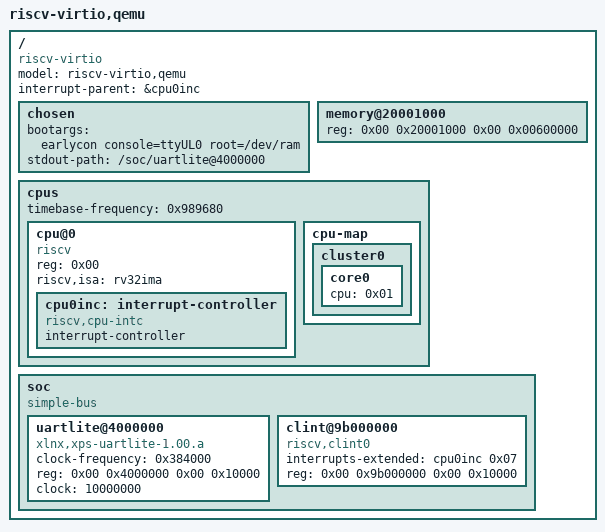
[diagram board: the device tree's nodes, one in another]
/dts-v1/;

/ {
	#address-cells = <0x02>;
	#size-cells = <0x02>;
	compatible = "riscv-virtio";
	model = "riscv-virtio,qemu";
	interrupt-parent = "&cpu0inc";

	chosen {
		bootargs = "earlycon console=ttyUL0 root=/dev/ram";
		stdout-path = "/soc/uartlite@4000000";
		/*bootargs = "earlycon console=ttyS0 root=/dev/ram";*/
		/*stdout-path = "/soc/uart@40000000";*/
	};

	memory@20001000 {
		device_type = "memory";
		reg = <0x00 0x20001000 0x00 0x00600000>;
	};

	cpus {
		#address-cells = <0x01>;
		#size-cells = <0x00>;
		timebase-frequency = <0x989680>;

		cpu@0 {
			phandle = <0x01>;
			device_type = "cpu";
			reg = <0x00>;
			status = "okay";
			compatible = "riscv";
			riscv,isa = "rv32ima";
			//mmu-type = "riscv,sv32";

			cpu0inc: interrupt-controller {
				#interrupt-cells = <0x01>;
				#address-cells = <0x01>;
				interrupt-controller;
				compatible = "riscv,cpu-intc";
				//phandle = <0x02>;
			};
		};

		cpu-map {

			cluster0 {

				core0 {
					cpu = <0x01>;
				};
			};
		};
	};

	soc {
		#address-cells = <0x02>;
		#size-cells = <0x02>;
		compatible = "simple-bus";
		ranges;

		/*
		uart@40000000 {
			//interrupts = <0x0a>;
			//interrupt-parent = <0x03>;
			clock-frequency = <0x384000>;
			reg = <0x00 0x40000000 0x00 0x100>;
			compatible = "ns16550";
		};
	*/

		uartlite@4000000 {
			clock-frequency = <0x384000>;
			//interrupts = <0 59 4>;
			//interrupt-parent = <0x03>;
			compatible = "xlnx,xps-uartlite-1.00.a";
			reg = <0x00 0x4000000 0x00 0x10000>;
			clock = <10000000>;
		};

		clint@9b000000 {
			//interrupt-parent = <0x03>;
			//interrupts-extended = <&cpu0inc 0x03 &cpu0inc 0x07>;
			interrupts-extended = <&cpu0inc 0x07>;
			reg = <0x00 0x9b000000 0x00 0x10000>;
			compatible = "riscv,clint0";
		};


		/*uart@80000000 { // dummy*/
			/*[>interrupts = <0x0a>;<]*/
			/*[>interrupt-parent = <0x03>;<]*/
			/*clock-frequency = <0x384000>;*/
			/*reg = <0x00 0x80000000 0x00 0x100>;*/
			/*compatible = "ns16550";*/
		/*};*/
	};
};
